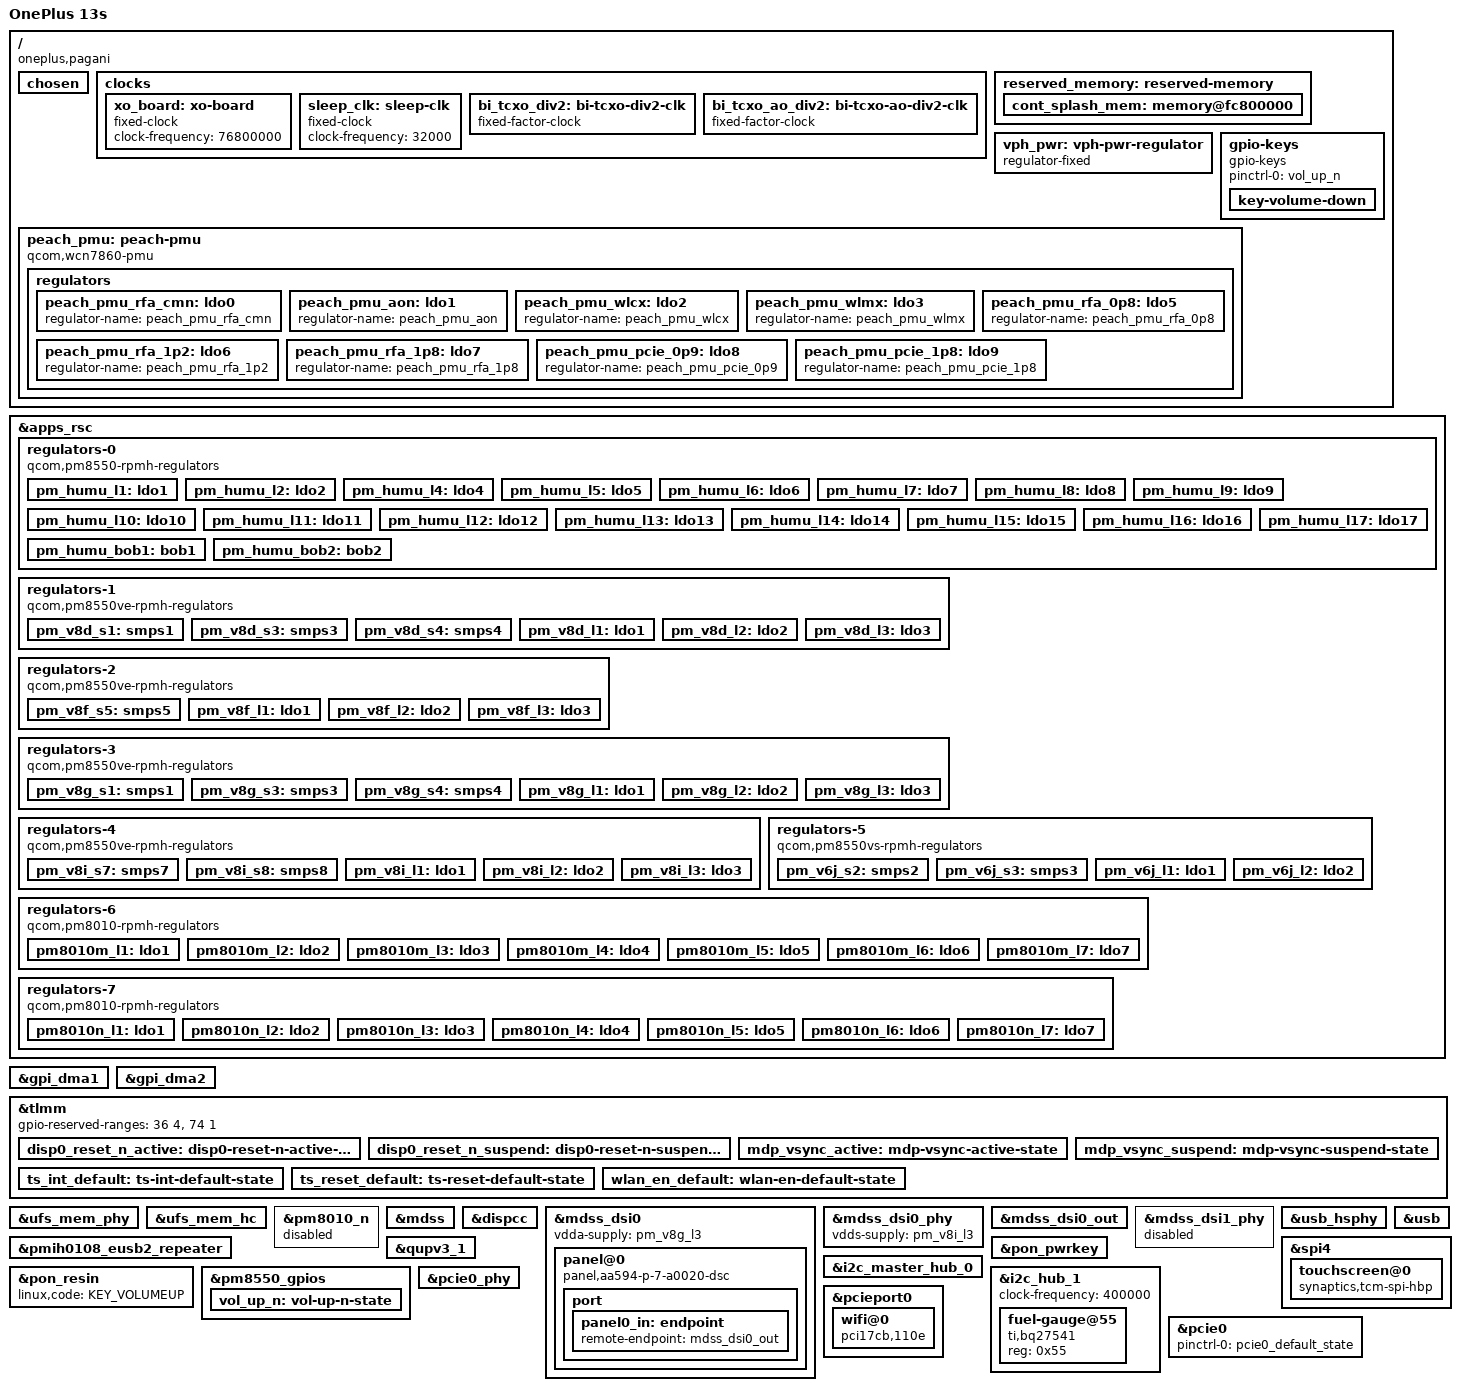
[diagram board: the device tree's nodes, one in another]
// SPDX-License-Identifier: BSD-3-Clause
/*
 * Copyright (c) 2025 renhiyama. All rights reserved.
 */

/dts-v1/;

#include <dt-bindings/gpio/gpio.h>
#include <dt-bindings/input/linux-event-codes.h>
#include <dt-bindings/leds/common.h>
#include <dt-bindings/regulator/qcom,rpmh-regulator.h>
#include "sm8750.dtsi"
//#include <dt-bindings/spmi/spmi.h>
#include "pm8010.dtsi"
#include "pm8550.dtsi"
#define PMK8550VE_SID 8
#include "pm8550ve.dtsi"
#include "pmih0108.dtsi"
#include "pmk8550.dtsi"
#include "pmr735d_a.dtsi"
#include "sm8750-pmics.dtsi"

/ {
	model = "OnePlus 13s";
	compatible = "oneplus,pagani", "qcom,sm8750";
	chassis-type = "handset";

	chosen {
		bootargs = "rootwait rw initcall_debug ignore_loglevel clk_ignore_unused pd_ignore_unused root=UUID=3a735709-c490-4c3e-a2a1-6cfeba270749";
		stdout-path = "fb0";

		#address-cells = <2>;
		#size-cells = <2>;
		ranges;

		/*
		 * No simple-framebuffer node: the UEFI (Mu-Silicium) GOP
		 * framebuffer is handed to the kernel via EFI, so efifb claims
		 * fb0 instead of simplefb. cont_splash_mem below keeps the
		 * fc800000 region reserved for it.
		 */
	};

	clocks {
		xo_board: xo-board {
			#clock-cells = <0>;

			compatible = "fixed-clock";
			clock-frequency = <76800000>;
		};

		sleep_clk: sleep-clk {
			#clock-cells = <0>;

			compatible = "fixed-clock";
			clock-frequency = <32000>;
		};

		bi_tcxo_div2: bi-tcxo-div2-clk {
			#clock-cells = <0>;

			compatible = "fixed-factor-clock";

			clocks = <&rpmhcc RPMH_CXO_CLK>;
			clock-mult = <1>;
			clock-div = <2>;
		};

		bi_tcxo_ao_div2: bi-tcxo-ao-div2-clk {
			#clock-cells = <0>;

			compatible = "fixed-factor-clock";

			clocks = <&rpmhcc RPMH_CXO_CLK_A>;
			clock-mult = <1>;
			clock-div = <2>;
		};
	};

	reserved_memory: reserved-memory {
		#address-cells = <2>;
		#size-cells = <2>;
		ranges;

		cont_splash_mem: memory@fc800000 {
			reg = <0x0 0xfc800000 0x0 0x2b00000>;
			no-map;
		};
	};

	vph_pwr: vph-pwr-regulator {
		compatible = "regulator-fixed";

		regulator-name = "vph_pwr";
		regulator-min-microvolt = <3700000>;
		regulator-max-microvolt = <3700000>;

		regulator-always-on;
		regulator-boot-on;
	};
};

&apps_rsc {
	regulators-0 {
		compatible = "qcom,pm8550-rpmh-regulators";
		qcom,pmic-id = "b";

		vdd-bob1-supply = <&vph_pwr>;
		vdd-bob2-supply = <&vph_pwr>;
		vdd-l1-l4-l10-supply = <&pm_v8g_s3>;
		vdd-l2-l13-l14-supply = <&pm_humu_bob1>;
		vdd-l3-supply = <&pm_v8i_s7>;
		vdd-l5-l16-supply = <&pm_humu_bob1>;
		vdd-l6-l7-supply = <&pm_humu_bob1>;
		vdd-l8-l9-supply = <&pm_humu_bob1>;
		vdd-l11-supply = <&pm_v8i_s7>;
		vdd-l12-supply = <&pm_v8g_s3>;
		vdd-l15-supply = <&pm_v8g_s3>;
		vdd-l17-supply = <&pm_humu_bob2>;

		pm_humu_l1: ldo1 {
			regulator-name = "pm_humu_l1";
			regulator-min-microvolt = <1800000>;
			regulator-max-microvolt = <1800000>;
			regulator-initial-mode = <RPMH_REGULATOR_MODE_HPM>;
			regulator-allow-set-load;
			regulator-allowed-modes = <RPMH_REGULATOR_MODE_LPM
							RPMH_REGULATOR_MODE_HPM>;
		};

		pm_humu_l2: ldo2 {
			regulator-name = "pm_humu_l2";
			regulator-min-microvolt = <3008000>;
			regulator-max-microvolt = <3048000>;
			regulator-initial-mode = <RPMH_REGULATOR_MODE_HPM>;
			regulator-allow-set-load;
			regulator-allowed-modes = <RPMH_REGULATOR_MODE_LPM
							RPMH_REGULATOR_MODE_HPM>;
		};

		/* ldo4 = cmd-db "ldob4" (pmic-id b) = downstream L4B, the
		 * Synaptics touch VDD (~1.2V). Not consumed by anything else
		 * in this DTS. */
		pm_humu_l4: ldo4 {
			regulator-name = "pm_humu_l4";
			regulator-min-microvolt = <1200000>;
			regulator-max-microvolt = <1200000>;
			regulator-initial-mode = <RPMH_REGULATOR_MODE_HPM>;
			regulator-allow-set-load;
			regulator-allowed-modes = <RPMH_REGULATOR_MODE_LPM
							RPMH_REGULATOR_MODE_HPM>;
		};

		pm_humu_l5: ldo5 {
			regulator-name = "pm_humu_l5";
			regulator-min-microvolt = <3100000>;
			regulator-max-microvolt = <3148000>;
			regulator-initial-mode = <RPMH_REGULATOR_MODE_HPM>;
			regulator-allow-set-load;
			regulator-allowed-modes = <RPMH_REGULATOR_MODE_LPM
							RPMH_REGULATOR_MODE_HPM>;
		};

		pm_humu_l6: ldo6 {
			regulator-name = "pm_humu_l6";
			regulator-min-microvolt = <1800000>;
			regulator-max-microvolt = <3008000>;
			regulator-initial-mode = <RPMH_REGULATOR_MODE_HPM>;
			regulator-allow-set-load;
			regulator-allowed-modes = <RPMH_REGULATOR_MODE_LPM
							RPMH_REGULATOR_MODE_HPM>;
		};

		pm_humu_l7: ldo7 {
			regulator-name = "pm_humu_l7";
			regulator-min-microvolt = <1800000>;
			regulator-max-microvolt = <3008000>;
			regulator-initial-mode = <RPMH_REGULATOR_MODE_HPM>;
			regulator-allow-set-load;
			regulator-allowed-modes = <RPMH_REGULATOR_MODE_LPM
							RPMH_REGULATOR_MODE_HPM>;
		};

		/*
		 * L8B is the WLAN/BT shared-antenna switch rail
		 * (vdd-wlan-ant-share, 2.8V) on pagani. cnss enables it
		 * during bringup; the WCN7880 RF cal transmits through the
		 * shared-antenna front-end, so without this rail the TX path
		 * is dead and the on-chip cal fails with "ytx_acc power fail".
		 * ath12k/pwrseq has no ant-share supply binding, so keep this
		 * dedicated rail on at the fixed 2.8V the board expects.
		 */
		pm_humu_l8: ldo8 {
			regulator-name = "pm_humu_l8";
			regulator-min-microvolt = <2800000>;
			regulator-max-microvolt = <2800000>;
			regulator-initial-mode = <RPMH_REGULATOR_MODE_HPM>;
			regulator-allow-set-load;
			regulator-allowed-modes = <RPMH_REGULATOR_MODE_LPM
							RPMH_REGULATOR_MODE_HPM>;
			regulator-always-on;
			regulator-boot-on;
		};

		pm_humu_l9: ldo9 {
			regulator-name = "pm_humu_l9";
			regulator-min-microvolt = <2960000>;
			regulator-max-microvolt = <3104000>;
			regulator-initial-mode = <RPMH_REGULATOR_MODE_HPM>;
			regulator-allow-set-load;
			regulator-allowed-modes = <RPMH_REGULATOR_MODE_LPM
							RPMH_REGULATOR_MODE_HPM>;
		};

		pm_humu_l10: ldo10 {
			regulator-name = "pm_humu_l10";
			regulator-min-microvolt = <1800000>;
			regulator-max-microvolt = <1800000>;
			regulator-initial-mode = <RPMH_REGULATOR_MODE_HPM>;
			regulator-allow-set-load;
			regulator-allowed-modes = <RPMH_REGULATOR_MODE_LPM
							RPMH_REGULATOR_MODE_HPM>;
		};

		pm_humu_l11: ldo11 {
			regulator-name = "pm_humu_l11";
			regulator-min-microvolt = <1064000>;
			regulator-max-microvolt = <1292000>;
			regulator-initial-mode = <RPMH_REGULATOR_MODE_HPM>;
			regulator-allow-set-load;
			regulator-allowed-modes = <RPMH_REGULATOR_MODE_LPM
							RPMH_REGULATOR_MODE_HPM>;
		};

		pm_humu_l12: ldo12 {
			regulator-name = "pm_humu_l12";
			/* dedicated panel vddio, pin to 1.8V (panel driver does
			 * not set the voltage); downstream uses 1800000 fixed */
			regulator-min-microvolt = <1800000>;
			regulator-max-microvolt = <1800000>;
			regulator-initial-mode = <RPMH_REGULATOR_MODE_HPM>;
			regulator-allow-set-load;
			regulator-allowed-modes = <RPMH_REGULATOR_MODE_LPM
							RPMH_REGULATOR_MODE_HPM>;
		};

		pm_humu_l13: ldo13 {
			regulator-name = "pm_humu_l13";
			regulator-min-microvolt = <3000000>;
			regulator-max-microvolt = <3000000>;
			regulator-initial-mode = <RPMH_REGULATOR_MODE_HPM>;
			regulator-allow-set-load;
			regulator-allowed-modes = <RPMH_REGULATOR_MODE_LPM
							RPMH_REGULATOR_MODE_HPM>;
		};

		pm_humu_l14: ldo14 {
			regulator-name = "pm_humu_l14";
			regulator-min-microvolt = <2800000>;
			regulator-max-microvolt = <2800000>;
			regulator-initial-mode = <RPMH_REGULATOR_MODE_HPM>;
			regulator-allow-set-load;
			regulator-allowed-modes = <RPMH_REGULATOR_MODE_LPM
							RPMH_REGULATOR_MODE_HPM>;
		};

		pm_humu_l15: ldo15 {
			regulator-name = "pm_humu_l15";
			regulator-min-microvolt = <1800000>;
			regulator-max-microvolt = <1800000>;
			regulator-initial-mode = <RPMH_REGULATOR_MODE_HPM>;
			regulator-allow-set-load;
			regulator-allowed-modes = <RPMH_REGULATOR_MODE_LPM
							RPMH_REGULATOR_MODE_HPM>;
		};

		/* ldo16 = cmd-db "ldob16" (pmic-id b) = downstream L16B, the
		 * Synaptics touch AVDD (~3.0V). Same pldo type as l13 which
		 * works at 3.0V, so the earlier probe failure was a bad
		 * voltage constraint, not the rail itself. */
		pm_humu_l16: ldo16 {
			regulator-name = "pm_humu_l16";
			regulator-min-microvolt = <3000000>;
			regulator-max-microvolt = <3000000>;
			regulator-initial-mode = <RPMH_REGULATOR_MODE_HPM>;
			regulator-allow-set-load;
			regulator-allowed-modes = <RPMH_REGULATOR_MODE_LPM
							RPMH_REGULATOR_MODE_HPM>;
		};

		pm_humu_l17: ldo17 {
			regulator-name = "pm_humu_l17";
			regulator-min-microvolt = <2504000>;
			regulator-max-microvolt = <2504000>;
			regulator-initial-mode = <RPMH_REGULATOR_MODE_HPM>;
			regulator-allow-set-load;
			regulator-allowed-modes = <RPMH_REGULATOR_MODE_LPM
							RPMH_REGULATOR_MODE_HPM>;
		};

		pm_humu_bob1: bob1 {
			regulator-name = "pm_humu_bob1";
			regulator-min-microvolt = <3008000>;
			regulator-max-microvolt = <4000000>;
			regulator-initial-mode = <RPMH_REGULATOR_MODE_HPM>;
		};

		pm_humu_bob2: bob2 {
			regulator-name = "pm_humu_bob2";
			regulator-min-microvolt = <2704000>;
			regulator-max-microvolt = <3008000>;
			regulator-initial-mode = <RPMH_REGULATOR_MODE_HPM>;
		};
	};

	regulators-1 {
		compatible = "qcom,pm8550ve-rpmh-regulators";
		qcom,pmic-id = "d";

		vdd-l1-supply = <&pm_v8i_s7>;
		vdd-l2-supply = <&pm_v8d_s1>;
		vdd-l3-supply = <&pm_v8d_s1>;
		vdd-s1-supply = <&vph_pwr>;
		vdd-s3-supply = <&vph_pwr>;
		vdd-s4-supply = <&vph_pwr>;

		pm_v8d_s1: smps1 {
			regulator-name = "pm_v8d_s1";
			regulator-min-microvolt = <880000>;
			regulator-max-microvolt = <1100000>;
			regulator-initial-mode = <RPMH_REGULATOR_MODE_HPM>;
		};

		pm_v8d_s3: smps3 {
			regulator-name = "pm_v8d_s3";
			regulator-min-microvolt = <1200000>;
			regulator-max-microvolt = <1300000>;
			regulator-initial-mode = <RPMH_REGULATOR_MODE_HPM>;
		};

		pm_v8d_s4: smps4 {
			regulator-name = "pm_v8d_s4";
			regulator-min-microvolt = <500000>;
			regulator-max-microvolt = <1036000>;
			regulator-initial-mode = <RPMH_REGULATOR_MODE_HPM>;
		};

		pm_v8d_l1: ldo1 {
			regulator-name = "pm_v8d_l1";
			regulator-min-microvolt = <1200000>;
			regulator-max-microvolt = <1200000>;
			regulator-initial-mode = <RPMH_REGULATOR_MODE_HPM>;
			regulator-allow-set-load;
			regulator-allowed-modes = <RPMH_REGULATOR_MODE_LPM
							RPMH_REGULATOR_MODE_HPM>;
		};

		pm_v8d_l2: ldo2 {
			regulator-name = "pm_v8d_l2";
			regulator-min-microvolt = <880000>;
			regulator-max-microvolt = <912000>;
			regulator-initial-mode = <RPMH_REGULATOR_MODE_HPM>;
			regulator-allow-set-load;
			regulator-allowed-modes = <RPMH_REGULATOR_MODE_LPM
							RPMH_REGULATOR_MODE_HPM>;
		};

		pm_v8d_l3: ldo3 {
			regulator-name = "pm_v8d_l3";
			regulator-min-microvolt = <880000>;
			regulator-max-microvolt = <920000>;
			regulator-initial-mode = <RPMH_REGULATOR_MODE_HPM>;
			regulator-allow-set-load;
			regulator-allowed-modes = <RPMH_REGULATOR_MODE_LPM
							RPMH_REGULATOR_MODE_HPM>;
		};
	};

	regulators-2 {
		compatible = "qcom,pm8550ve-rpmh-regulators";
		qcom,pmic-id = "f";

		vdd-l1-supply = <&pm_v8d_s1>;
		vdd-l2-supply = <&pm_v8i_s7>;
		vdd-l3-supply = <&pm_v8g_s3>;
		vdd-s5-supply = <&vph_pwr>;

		pm_v8f_s5: smps5 {
			regulator-name = "pm_v8f_s5";
			regulator-min-microvolt = <500000>;
			regulator-max-microvolt = <1000000>;
			regulator-initial-mode = <RPMH_REGULATOR_MODE_HPM>;
		};

		pm_v8f_l1: ldo1 {
			regulator-name = "pm_v8f_l1";
			regulator-min-microvolt = <880000>;
			regulator-max-microvolt = <920000>;
			regulator-initial-mode = <RPMH_REGULATOR_MODE_HPM>;
			regulator-allow-set-load;
			regulator-allowed-modes = <RPMH_REGULATOR_MODE_LPM
							RPMH_REGULATOR_MODE_HPM>;
		};
		pm_v8f_l2: ldo2 {
			regulator-name = "pm_v8f_l2";
			regulator-min-microvolt = <1200000>;
			regulator-max-microvolt = <1200000>;
			regulator-initial-mode = <RPMH_REGULATOR_MODE_HPM>;
			regulator-allow-set-load;
			regulator-allowed-modes = <RPMH_REGULATOR_MODE_LPM
							RPMH_REGULATOR_MODE_HPM>;
		};

		pm_v8f_l3: ldo3 {
			regulator-name = "pm_v8f_l3";
			regulator-min-microvolt = <1800000>;
			regulator-max-microvolt = <1800000>;
			regulator-initial-mode = <RPMH_REGULATOR_MODE_HPM>;
			regulator-allow-set-load;
			regulator-allowed-modes = <RPMH_REGULATOR_MODE_LPM
							RPMH_REGULATOR_MODE_HPM>;
		};
	};

	regulators-3 {
		compatible = "qcom,pm8550ve-rpmh-regulators";
		qcom,pmic-id = "g";

		vdd-l1-supply = <&pm_v8d_s1>;
		vdd-l2-supply = <&pm_v8g_s3>;
		vdd-l3-supply = <&pm_v8i_s7>;
		vdd-s1-supply = <&vph_pwr>;
		vdd-s3-supply = <&vph_pwr>;

		pm_v8g_s1: smps1 {
			regulator-name = "pm_v8g_s1";
			regulator-min-microvolt = <300000>;
			regulator-max-microvolt = <700000>;
			regulator-initial-mode = <RPMH_REGULATOR_MODE_HPM>;
		};

		pm_v8g_s3: smps3 {
			regulator-name = "pm_v8g_s3";
			regulator-min-microvolt = <1866000>;
			regulator-max-microvolt = <2000000>;
			regulator-initial-mode = <RPMH_REGULATOR_MODE_HPM>;
			regulator-allow-set-load;
			regulator-allowed-modes = <RPMH_REGULATOR_MODE_LPM
							RPMH_REGULATOR_MODE_HPM>;
		};

		pm_v8g_s4: smps4 {
			regulator-name = "pm_v8g_s4";
			regulator-min-microvolt = <300000>;
			regulator-max-microvolt = <900000>;
			regulator-initial-mode = <RPMH_REGULATOR_MODE_HPM>;
		};

		pm_v8g_l1: ldo1 {
			regulator-name = "pm_v8g_l1";
			regulator-min-microvolt = <912000>;
			regulator-max-microvolt = <936000>;
			regulator-initial-mode = <RPMH_REGULATOR_MODE_HPM>;
			regulator-allow-set-load;
			regulator-allowed-modes = <RPMH_REGULATOR_MODE_LPM
							RPMH_REGULATOR_MODE_HPM>;
		};

		pm_v8g_l2: ldo2 {
			regulator-name = "pm_v8g_l2";
			regulator-min-microvolt = <1200000>;
			regulator-max-microvolt = <1860000>;
			regulator-initial-mode = <RPMH_REGULATOR_MODE_HPM>;
			regulator-allow-set-load;
			regulator-allowed-modes = <RPMH_REGULATOR_MODE_LPM
							RPMH_REGULATOR_MODE_HPM>;
		};

		pm_v8g_l3: ldo3 {
			regulator-name = "pm_v8g_l3";
			regulator-min-microvolt = <1200000>;
			regulator-max-microvolt = <1256000>;
			regulator-initial-mode = <RPMH_REGULATOR_MODE_HPM>;
			regulator-allow-set-load;
			regulator-allowed-modes = <RPMH_REGULATOR_MODE_LPM
							RPMH_REGULATOR_MODE_HPM>;
		};
	};

	regulators-4 {
		compatible = "qcom,pm8550ve-rpmh-regulators";
		qcom,pmic-id = "i";

		vdd-l1-supply = <&pm_v8i_s7>;
		vdd-l2-supply = <&pm_v8i_s7>;
		vdd-l3-supply = <&pm_v8d_s1>;
		vdd-s7-supply = <&vph_pwr>;
		vdd-s8-supply = <&vph_pwr>;

		pm_v8i_s7: smps7 {
			regulator-name = "pm_v8i_s7";
			regulator-min-microvolt = <1224000>;
			regulator-max-microvolt = <1340000>;
			regulator-initial-mode = <RPMH_REGULATOR_MODE_HPM>;
		};

		pm_v8i_s8: smps8 {
			regulator-name = "pm_v8i_s8";
			regulator-min-microvolt = <900000>;
			regulator-max-microvolt = <972000>;
			regulator-initial-mode = <RPMH_REGULATOR_MODE_HPM>;
		};

		pm_v8i_l1: ldo1 {
			regulator-name = "pm_v8i_l1";
			regulator-min-microvolt = <1000000>;
			regulator-max-microvolt = <1000000>;
			regulator-initial-mode = <RPMH_REGULATOR_MODE_HPM>;
			regulator-allow-set-load;
			regulator-allowed-modes = <RPMH_REGULATOR_MODE_LPM
							RPMH_REGULATOR_MODE_HPM>;
		};

		pm_v8i_l2: ldo2 {
			regulator-name = "pm_v8i_l2";
			regulator-min-microvolt = <1200000>;
			regulator-max-microvolt = <1200000>;
			regulator-initial-mode = <RPMH_REGULATOR_MODE_HPM>;
			regulator-allow-set-load;
			regulator-allowed-modes = <RPMH_REGULATOR_MODE_LPM
							RPMH_REGULATOR_MODE_HPM>;
		};

		pm_v8i_l3: ldo3 {
			regulator-name = "pm_v8i_l3";
			regulator-min-microvolt = <880000>;
			regulator-max-microvolt = <912000>;
			regulator-initial-mode = <RPMH_REGULATOR_MODE_HPM>;
			regulator-allow-set-load;
			regulator-allowed-modes = <RPMH_REGULATOR_MODE_LPM
							RPMH_REGULATOR_MODE_HPM>;
		};
	};

	regulators-5 {
		compatible = "qcom,pm8550vs-rpmh-regulators";
		qcom,pmic-id = "j";

		vdd-l1-supply = <&pm_v8d_s1>;
		vdd-l2-supply = <&pm_v8i_s7>;
		vdd-s2-supply = <&vph_pwr>;
		vdd-s3-supply = <&vph_pwr>;
		// vdd-s4-supply = <&vph_pwr>;

		pm_v6j_s2: smps2 {
			regulator-name = "pm_v6j_s2";
			regulator-min-microvolt = <1000000>;
			regulator-max-microvolt = <1100000>;
			regulator-initial-mode = <RPMH_REGULATOR_MODE_HPM>;
		};

		pm_v6j_s3: smps3 {
			regulator-name = "pm_v6j_s3";
			regulator-min-microvolt = <1000000>;
			regulator-max-microvolt = <1100000>;
			regulator-initial-mode = <RPMH_REGULATOR_MODE_HPM>;
		};

		/*
		 * smps4 (RPMh resource "smpj4") does not exist on this PMIC, so
		 * it cannot be registered. Enabling it makes the qcom-rpmh-regulator
		 * probe for the whole regulators-5 node fail, which also drops
		 * pm_v6j_l1 (ldo1) - the UFS vdda-phy supplier - and bricks boot
		 * ("waiting for root"). Leave it disabled.
		 */
		// pm_v6j_s4: smps4 {
		// 	regulator-name = "pm_v6j_s4";
		// 	regulator-min-microvolt = <500000>;
		// 	regulator-max-microvolt = <1000000>;
		// 	regulator-initial-mode = <RPMH_REGULATOR_MODE_HPM>;
		// };

		pm_v6j_l1: ldo1 {
			regulator-name = "pm_v6j_l1";
			regulator-min-microvolt = <880000>;
			regulator-max-microvolt = <920000>;
			regulator-initial-mode = <RPMH_REGULATOR_MODE_HPM>;
			regulator-allow-set-load;
			regulator-allowed-modes = <RPMH_REGULATOR_MODE_LPM
							RPMH_REGULATOR_MODE_HPM>;
		};

		pm_v6j_l2: ldo2 {
			regulator-name = "pm_v6j_l2";
			regulator-min-microvolt = <1200000>;
			regulator-max-microvolt = <1200000>;
			regulator-initial-mode = <RPMH_REGULATOR_MODE_HPM>;
			regulator-allow-set-load;
			regulator-allowed-modes = <RPMH_REGULATOR_MODE_LPM
							RPMH_REGULATOR_MODE_HPM>;
		};
	};

	/*
	* NOTE: Currently `PMR735D` isn't mainlined in Linux Kernel, so I kept
	* this section commented out until proper support is added (if ever).

	regulators-6 {
		compatible = "";
		qcom,pmic-id = "k";

		// TODO: LDO Supplies here!

		pmr_nalojr_l1: ldo1 {
			regulator-name = "pmr_nalojr_l1";
			regulator-min-microvolt = <400000>;
			regulator-max-microvolt = <920000>;
		};

		pmr_nalojr_l2: ldo2 {
			regulator-name = "pmr_nalojr_l2";
			regulator-min-microvolt = <912000>;
			regulator-max-microvolt = <1000000>;
		};

		pmr_nalojr_l3: ldo3 {
			regulator-name = "pmr_nalojr_l3";
			regulator-min-microvolt = <1200000>;
			regulator-max-microvolt = <1200000>;
		};

		pmr_nalojr_l4: ldo4 {
			regulator-name = "pmr_nalojr_l4";
			regulator-min-microvolt = <1200000>;
			regulator-max-microvolt = <1200000>;
		};

		pmr_nalojr_l5: ldo5 {
			regulator-name = "pmr_nalojr_l5";
			regulator-min-microvolt = <952000>;
			regulator-max-microvolt = <976000>;
		};

		pmr_nalojr_l6: ldo6 {
			regulator-name = "pmr_nalojr_l6";
			regulator-min-microvolt = <1776000>;
			regulator-max-microvolt = <1860000>;
		};

		pmr_nalojr_l7: ldo7 {
			regulator-name = "pmr_nalojr_l7";
			regulator-min-microvolt = <800000>;
			regulator-max-microvolt = <800000>;
		};
	};
	*/

	regulators-6 {
		compatible = "qcom,pm8010-rpmh-regulators";
		qcom,pmic-id = "m";

		vdd-l1-l2-supply = <&pm_v8i_s7>;
		vdd-l3-l4-supply = <&pm_humu_bob2>;
		vdd-l5-supply = <&pm_v8g_s3>;
		vdd-l6-supply = <&pm_humu_bob1>;
		vdd-l7-supply = <&pm_humu_bob1>;

		pm8010m_l1: ldo1 {
			regulator-name = "pm8010m_l1";
			regulator-min-microvolt = <1100000>;
			regulator-max-microvolt = <1100000>;
			regulator-initial-mode = <RPMH_REGULATOR_MODE_HPM>;
			regulator-allow-set-load;
			regulator-allowed-modes = <RPMH_REGULATOR_MODE_LPM
							RPMH_REGULATOR_MODE_HPM>;
		};

		pm8010m_l2: ldo2 {
			regulator-name = "pm8010m_l2";
			regulator-min-microvolt = <1100000>;
			regulator-max-microvolt = <1100000>;
			regulator-initial-mode = <RPMH_REGULATOR_MODE_HPM>;
			regulator-allow-set-load;
			regulator-allowed-modes = <RPMH_REGULATOR_MODE_LPM
							RPMH_REGULATOR_MODE_HPM>;
		};

		pm8010m_l3: ldo3 {
			regulator-name = "pm8010m_l3";
			regulator-min-microvolt = <2800000>;
			regulator-max-microvolt = <2900000>;
			regulator-initial-mode = <RPMH_REGULATOR_MODE_HPM>;
		};

		pm8010m_l4: ldo4 {
			regulator-name = "pm8010m_l4";
			regulator-min-microvolt = <2200000>;
			regulator-max-microvolt = <2200000>;
			regulator-initial-mode = <RPMH_REGULATOR_MODE_HPM>;
		};

		pm8010m_l5: ldo5 {
			regulator-name = "pm8010m_l5";
			regulator-min-microvolt = <1800000>;
			regulator-max-microvolt = <1800000>;
			regulator-initial-mode = <RPMH_REGULATOR_MODE_HPM>;
		};

		pm8010m_l6: ldo6 {
			regulator-name = "pm8010m_l6";
			regulator-min-microvolt = <1800000>;
			regulator-max-microvolt = <1800000>;
			regulator-initial-mode = <RPMH_REGULATOR_MODE_HPM>;
		};

		pm8010m_l7: ldo7 {
			regulator-name = "pm8010m_l7";
			regulator-min-microvolt = <2800000>;
			regulator-max-microvolt = <3000000>;
			regulator-initial-mode = <RPMH_REGULATOR_MODE_HPM>;
		};
	};

	regulators-7 {
		compatible = "qcom,pm8010-rpmh-regulators";
		qcom,pmic-id = "n";

		vdd-l1-l2-supply = <&pm_v8i_s7>;
		vdd-l3-l4-supply = <&pm_v8g_s3>;
		vdd-l5-supply = <&pm_humu_bob2>;
		vdd-l6-supply = <&pm_humu_bob2>;
		vdd-l7-supply = <&pm_humu_bob1>;

		pm8010n_l1: ldo1 {
			regulator-name = "pm8010n_l1";
			regulator-min-microvolt = <800000>;
			regulator-max-microvolt = <1104000>;
			regulator-initial-mode = <RPMH_REGULATOR_MODE_HPM>;
			regulator-allow-set-load;
			regulator-allowed-modes = <RPMH_REGULATOR_MODE_LPM
							RPMH_REGULATOR_MODE_HPM>;
		};

		pm8010n_l2: ldo2 {
			regulator-name = "pm8010n_l2";
			regulator-min-microvolt = <800000>;
			regulator-max-microvolt = <1104000>;
			regulator-initial-mode = <RPMH_REGULATOR_MODE_HPM>;
			regulator-allow-set-load;
			regulator-allowed-modes = <RPMH_REGULATOR_MODE_LPM
							RPMH_REGULATOR_MODE_HPM>;
		};

		pm8010n_l3: ldo3 {
			regulator-name = "pm8010n_l3";
			regulator-min-microvolt = <2800000>;
			regulator-max-microvolt = <2800000>;
			regulator-initial-mode = <RPMH_REGULATOR_MODE_HPM>;
		};

		pm8010n_l4: ldo4 {
			regulator-name = "pm8010n_l4";
			regulator-min-microvolt = <2800000>;
			regulator-max-microvolt = <2800000>;
			regulator-initial-mode = <RPMH_REGULATOR_MODE_HPM>;
		};

		pm8010n_l5: ldo5 {
			regulator-name = "pm8010n_l5";
			regulator-min-microvolt = <2800000>;
			regulator-max-microvolt = <3304000>;
			regulator-initial-mode = <RPMH_REGULATOR_MODE_HPM>;
		};

		pm8010n_l6: ldo6 {
			regulator-name = "pm8010n_l6";
			regulator-min-microvolt = <1800000>;
			regulator-max-microvolt = <1800000>;
			regulator-initial-mode = <RPMH_REGULATOR_MODE_HPM>;
		};

		pm8010n_l7: ldo7 {
			regulator-name = "pm8010n_l7";
			regulator-min-microvolt = <3304000>;
			regulator-max-microvolt = <3304000>;
			regulator-initial-mode = <RPMH_REGULATOR_MODE_HPM>;
		};
	};
};

&gpi_dma1 {
	status = "okay";
};

&gpi_dma2 {
	status = "okay";
};

&tlmm {
	gpio-reserved-ranges = <36 4>, <74 1>;
};

&ufs_mem_phy {
	vdda-phy-supply = <&pm_v6j_l1>;
	vdda-pll-supply = <&pm_v8g_l3>;

	status = "okay";
};

&ufs_mem_hc {
	reset-gpios = <&tlmm 215 GPIO_ACTIVE_LOW>;

	vcc-supply = <&pm_humu_l17>;
	vcc-max-microamp = <1300000>;
	vccq-supply = <&pm_v8d_l1>;
	vccq-max-microamp = <1200000>;

	status = "okay";
};

&pm8010_n {
  status = "disabled";
};

&mdss {
	status = "okay";
};

&dispcc {
	status = "okay";
};

&mdss_dsi0 {
	vdda-supply = <&pm_v8g_l3>;
	status = "okay";

	panel@0 {
		compatible = "panel,aa594-p-7-a0020-dsc";
		reg = <0>;

		pinctrl-names = "default", "sleep";
		pinctrl-0 = <&disp0_reset_n_active>, <&mdp_vsync_active>;
		pinctrl-1 = <&disp0_reset_n_suspend>, <&mdp_vsync_suspend>;

		vddio-supply = <&pm_humu_l12>;
		vci-supply = <&pm_humu_l13>;

		reset-gpios = <&tlmm 98 GPIO_ACTIVE_LOW>;

		port {
			panel0_in: endpoint {
				remote-endpoint = <&mdss_dsi0_out>;
			};
		};
	};
};

&mdss_dsi0_phy {
	vdds-supply = <&pm_v8i_l3>;
	status = "okay";
};

&mdss_dsi0_out {
	remote-endpoint = <&panel0_in>;
	data-lanes = <0 1 2 3>;
};

/* second DSI link unused on pagani */
&mdss_dsi1_phy {
	status = "disabled";
};

&tlmm {
	disp0_reset_n_active: disp0-reset-n-active-state {
		pins = "gpio98";
		function = "gpio";
		drive-strength = <8>;
		bias-disable;
	};

	disp0_reset_n_suspend: disp0-reset-n-suspend-state {
		pins = "gpio98";
		function = "gpio";
		drive-strength = <2>;
		bias-pull-down;
	};

	mdp_vsync_active: mdp-vsync-active-state {
		pins = "gpio86";
		function = "mdp_vsync";
		drive-strength = <2>;
		bias-pull-down;
	};

	mdp_vsync_suspend: mdp-vsync-suspend-state {
		pins = "gpio86";
		function = "mdp_vsync";
		drive-strength = <2>;
		bias-pull-down;
	};
};

&pmih0108_eusb2_repeater {
	vdd18-supply = <&pm_humu_l15>;
	vdd3-supply = <&pm_humu_l5>;

	status = "okay";
};

&usb_hsphy {
	vdd-supply = <&pm_v8d_l2>;
	vdda12-supply = <&pm_v8g_l3>;

	phys = <&pmih0108_eusb2_repeater>;

	status = "okay";
};

&usb {
	dr_mode = "peripheral";
	/delete-property/ usb-role-switch;

	/*
	 * No Type-C port-manager (pmic_glink) on this board, so the QMP combo
	 * SS phy can't acquire its DP drm_bridge ("aux_bridge ... -ENODEV")
	 * and never probes, which left dwc3 waiting on usb3-phy forever and no
	 * UDC registered. Drop SS and run gadget HS-only (usb-net needs only
	 * high speed); dwc3 then needs just the built-in m31 eusb2 phy.
	 */
	phys = <&usb_hsphy>;
	phy-names = "usb2-phy";
	maximum-speed = "high-speed";

	status = "okay";
};

/*
 * QUPv3 SE4 SPI = downstream qupv3_se4_spi, the bus the Synaptics S3910
 * touch controller (synaptics,tcm-spi-hbp) sits on. Phase A: bring the
 * SPI master up so the SE enumerates; touch child node added with the
 * driver. Pins come from the node's own qup_spi4_data_clk/qup_spi4_cs.
 * The parent QUPv3_1 wrapper is disabled by default in sm8750.dtsi, so
 * it must be enabled too or the child SE never probes.
 */
&qupv3_1 {
	status = "okay";
};

&spi4 {
	status = "okay";

	touchscreen@0 {
		compatible = "synaptics,tcm-spi-hbp";
		reg = <0>;
		spi-max-frequency = <19000000>;

		vcc-supply = <&pm_humu_l16>;
		vdd-supply = <&pm_humu_l4>;

		interrupt-parent = <&tlmm>;
		interrupts = <162 IRQ_TYPE_LEVEL_LOW>;
		reset-gpios = <&tlmm 161 GPIO_ACTIVE_LOW>;

		pinctrl-names = "default";
		pinctrl-0 = <&ts_int_default>, <&ts_reset_default>;
	};
};

/*
 * Synaptics S3910 touch attention (gpio162) and reset (gpio161) lines.
 * Power rails (vcc/vdd from the pmxr2230 PMIC) are not modelled in mainline
 * yet and are left enabled by the bootloader, so they are omitted here and
 * the driver treats its regulators as optional.
 */
&tlmm {
	ts_int_default: ts-int-default-state {
		pins = "gpio162";
		function = "gpio";
		bias-disable;
		input-enable;
	};

	ts_reset_default: ts-reset-default-state {
		pins = "gpio161";
		function = "gpio";
		bias-disable;
		drive-strength = <8>;
	};
};

/*
 * Hardware buttons:
 *   power      = pmk8550 PON pwrkey  -> KEY_POWER
 *   volume-up  = pmk8550 PON resin   -> KEY_VOLUMEUP
 *   volume-down= pm8550 gpio6        -> KEY_VOLUMEDOWN (gpio-keys)
 */
&pon_pwrkey {
	status = "okay";
};

&pon_resin {
	linux,code = <KEY_VOLUMEUP>;
	status = "okay";
};

&pm8550_gpios {
	vol_up_n: vol-up-n-state {
		pins = "gpio6";
		function = "normal";
		bias-pull-up;
		input-enable;
		power-source = <1>;
	};
};

/ {
	gpio-keys {
		compatible = "gpio-keys";

		pinctrl-names = "default";
		pinctrl-0 = <&vol_up_n>;

		key-volume-down {
			label = "Volume Down";
			gpios = <&pm8550_gpios 6 GPIO_ACTIVE_LOW>;
			linux,code = <KEY_VOLUMEDOWN>;
			debounce-interval = <15>;
		};
	};
};

/*
 * Battery fuel gauge: TI BQ27541 at I2C 0x55 on the QUPv3 I2C master-hub
 * SE1 (downstream qupv3_hub_i2c1). Read directly by the AP over I2C - no
 * DSP/firmware needed - giving voltage/current/charge/capacity via the
 * mainline bq27xxx driver. (The OnePlus charger DSP path is separate; this
 * is just the gauge for battery stats.)
 */
&i2c_master_hub_0 {
	status = "okay";
};

&i2c_hub_1 {
	clock-frequency = <400000>;
	status = "okay";

	fuel-gauge@55 {
		compatible = "ti,bq27541";
		reg = <0x55>;
	};
};

/*
 * WiFi - Qualcomm "peach" (WCN7860-class, WiFi-7), PCIe 17cb:110e.
 *
 * Powered via the mainline WCN power-sequencing path:
 *   - peach_pmu (pwrseq-qcom-wcn, compatible "qcom,wcn7860-pmu") brings up the
 *     chip's board input rails and asserts wlan-enable (gpio16).
 *   - pci-pwrctrl-pwrseq matches the wifi@0 endpoint by "pci17cb,110e" and runs
 *     that sequence when the PCIe root port enumerates, so the chip is powered
 *     independently of ath12k and shows up on the bus before the WLAN driver
 *     binds (M2). Both the pwrseq vreg set and the pwrctl PCI id are added in
 *     0003-wifi-peach-pwrseq-support.patch.
 *
 * Rail map (downstream sun-peach-cnss -> mainline RPMH label, by pmic-id):
 *   io 1.8   L3F -> pm_v8f_l3   io12 1.2 L2F -> pm_v8f_l2
 *   aon      S4D -> pm_v8d_s4   rfa1     S3G -> pm_v8g_s3 (~1.9V)
 *   rfa2     S7I -> pm_v8i_s7 (~1.3V, shared rail)
 *   dig      S5F -> pm_v8f_s5 (~0.9V; per sun-peach-cnss-v8 - the v8 board
 *            variant pagani uses, NOT the base cnss dtsi which lists S4J/smpj4
 *            that this platform's cmd-db does not expose).
 * PCIe RC0 pins (sm8750.dtsi pcie0_default_state): perst gpio102, clkreq
 * gpio103, wake gpio104. PHY 0.88/1.2 supplies off pmic-i (mirrors sm8650-qrd).
 */
&pcie0 {
	pinctrl-names = "default";
	pinctrl-0 = <&pcie0_default_state>;

	status = "okay";
};

&pcie0_phy {
	vdda-phy-supply = <&pm_v8i_l3>;
	vdda-pll-supply = <&pm_v8i_l2>;

	status = "okay";
};

&pcieport0 {
	wake-gpios = <&tlmm 104 GPIO_ACTIVE_HIGH>;
	reset-gpios = <&tlmm 102 GPIO_ACTIVE_LOW>;

	wifi@0 {
		compatible = "pci17cb,110e";
		reg = <0x10000 0x0 0x0 0x0 0x0>;

		qcom,qmp = <&aoss_qmp>;
		vddrfacmn-supply = <&peach_pmu_rfa_cmn>;
		vddaon-supply = <&peach_pmu_aon>;
		vddwlcx-supply = <&peach_pmu_wlcx>;
		vddwlmx-supply = <&peach_pmu_wlmx>;
		vddrfa0p8-supply = <&peach_pmu_rfa_0p8>;
		vddrfa1p2-supply = <&peach_pmu_rfa_1p2>;
		vddrfa1p8-supply = <&peach_pmu_rfa_1p8>;
		vddpcie0p9-supply = <&peach_pmu_pcie_0p9>;
		vddpcie1p8-supply = <&peach_pmu_pcie_1p8>;
	};
};

/*
 * aon is a dedicated WLAN-only rail (no other consumer), so raise its floor to
 * the peach spec minimum (0.876V); the stock 0.5V floor left it undervolted and
 * the chip's PMU never released.
 */
&pm_v8d_s4 {
	regulator-min-microvolt = <876000>;
};

/* dig is a dedicated WLAN-only rail; pin its floor to the peach spec (0.876V). */
&pm_v8f_s5 {
	regulator-min-microvolt = <876000>;
};

/*
 * rfa2 (peach vdd-wlan-rfa2) wants 1.312-1.34V; the shared pm_v8i_s7 SMPS sits
 * at its 1.224V floor by default, below the peach minimum. Raise the floor to
 * 1.312V - within the SMPS range (1.224-1.34V) and above every downstream LDO
 * output it feeds, so other consumers are unaffected.
 */
&pm_v8i_s7 {
	regulator-min-microvolt = <1312000>;
};

/ {
	peach_pmu: peach-pmu {
		compatible = "qcom,wcn7860-pmu";

		pinctrl-names = "default";
		pinctrl-0 = <&wlan_en_default>;

		wlan-enable-gpios = <&tlmm 16 GPIO_ACTIVE_HIGH>;

		vddio-supply = <&pm_v8f_l3>;
		vddio1p2-supply = <&pm_v8f_l2>;
		vddaon-supply = <&pm_v8d_s4>;
		vdddig-supply = <&pm_v8f_s5>;
		vddrfa1p2-supply = <&pm_v8i_s7>;
		vddrfa1p8-supply = <&pm_v8g_s3>;

		clocks = <&rpmhcc RPMH_RF_CLK1>;

		regulators {
			peach_pmu_rfa_cmn: ldo0 {
				regulator-name = "peach_pmu_rfa_cmn";
			};

			peach_pmu_aon: ldo1 {
				regulator-name = "peach_pmu_aon";
			};

			peach_pmu_wlcx: ldo2 {
				regulator-name = "peach_pmu_wlcx";
			};

			peach_pmu_wlmx: ldo3 {
				regulator-name = "peach_pmu_wlmx";
			};

			peach_pmu_rfa_0p8: ldo5 {
				regulator-name = "peach_pmu_rfa_0p8";
			};

			peach_pmu_rfa_1p2: ldo6 {
				regulator-name = "peach_pmu_rfa_1p2";
			};

			peach_pmu_rfa_1p8: ldo7 {
				regulator-name = "peach_pmu_rfa_1p8";
			};

			peach_pmu_pcie_0p9: ldo8 {
				regulator-name = "peach_pmu_pcie_0p9";
			};

			peach_pmu_pcie_1p8: ldo9 {
				regulator-name = "peach_pmu_pcie_1p8";
			};
		};
	};
};

&tlmm {
	wlan_en_default: wlan-en-default-state {
		pins = "gpio16";
		function = "gpio";
		drive-strength = <2>;
		bias-pull-down;
		output-low;
	};
};
